# PCIE1_CORE_DBN_CFG_PCIE_CORE register map
Vendor: Texas Instruments
Registers are 32-bit, read-write, reset 0x0 unless marked. A register's access mark holds for its fields unless they carry their own. Offsets are as the file gives them; [hi:lo] are bit positions; {n}, {i} and the like mark numbered series; 'fields as' and 'values as' point back to an identical list.

## PCIE1_CORE_DBN_CFG_PCIE_CORE (part 5 of 7)
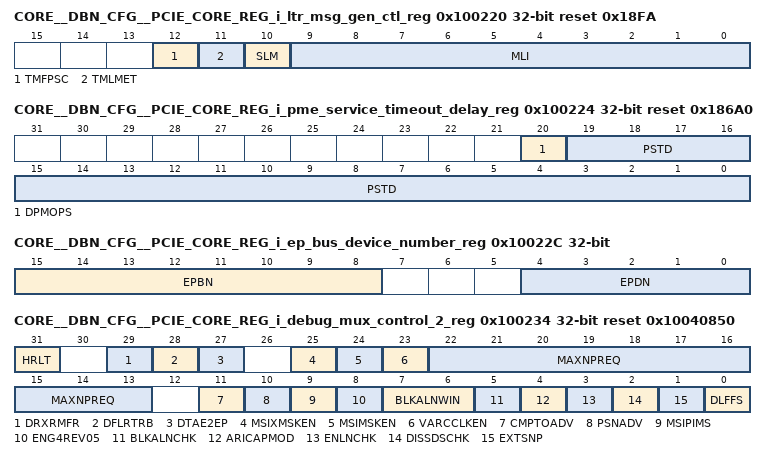
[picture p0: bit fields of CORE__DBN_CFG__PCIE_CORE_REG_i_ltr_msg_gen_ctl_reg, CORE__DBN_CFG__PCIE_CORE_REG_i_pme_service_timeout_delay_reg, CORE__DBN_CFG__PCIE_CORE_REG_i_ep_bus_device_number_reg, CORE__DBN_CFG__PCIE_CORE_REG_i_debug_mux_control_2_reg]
0x100220 CORE__DBN_CFG__PCIE_CORE_REG_i_ltr_msg_gen_ctl_reg access per field reset 0x18FA — This register contains fields for the generation of Latency Tolerance Reporting (LTR) Messages. This register is to be used only when the Controller is configured in the EndPoint mode.
  [12] TMFPSC rw — When this bit is set to 1, the Controller will automatically transmit an LTR message when all the Functions in the Controller have transitioned to a non-D0 power state, provided that the following conditions are both true: 1. The Controller sent at least one LTR message since the Data Link layer last transitioned from down to up state. 2. The most recent LTR message transmitted by the Controller had as least one of the Requirement bits set. The Controller will set the Requirement bits in this LTR message to 0. When this bit 12 is 0, the Controller will not, by itself, send any LTR messages in response to Function Power State changes. Client logic may monitor the FUNCTION_POWER_STATE outputs of the Controller and transmit LTR messages through the master interface, in response to changes in their states.
  [11] TMLMET rw — When this bit is set to 1, the Controller will automatically transmit an LTR message whenever the LTR Mechanism Enable bit in the Device Control 2 Register changes from 0 to 1, with the parameters specified in the LTR Snoop/No-Snoop Latency Register. When this bit is 1, the Controller will also transmit an LTR message whenever the LTR Mechanism Enable bit is cleared, if the following conditions are both true: 1. The Controller sent at least one LTR message since the LTR Mechanism Enable bit was last set. 2. The most recent LTR message transmitted by the Controller had as least one of the Requirement bits set. The Controller will set the Requirement bits in this LTR message to 0. When this bit 11 is 0, the Controller will not, by itself, send any LTR messages in response to state changes of the LTR Mechanism Enable bit. Client logic may monitor the state of the LTR_MECHANISM_ ENABLE output of the Controller and transmit LTR messages through the master interface, in response to its state changes.
  [10] SLM ro — Setting this bit causes the Controller to transmit an LTR message with the parameters specified in the LTR Snoop/No-Snoop Latency Register [Section 8.4.2.9]. This bit is cleared by the Controller on transmitting the LTR message, and stays set until then. Client software must read this register and verify that this bit is 0 before setting it again to send a new message. This field becomes writable when LTR mechanism is enabled in device control-2 register.
  [9:0] MLI rw — This field specifies the minimum spacing between LTR messages transmitted by the Controller in units of microseconds. The PCI Express Specifications recommend sending no more than two LTR messages within a 500 microsecond interval. The Controller will wait for the minimum delay specified by this field after sending an LTR message, before transmitting a new LTR message. NOTE: The LINK can be in low power states[L0s and L1] when send LTR Message is trigered. So, the user has to consider the exit latencies while programming this field. It is recommended to program this field with about 2 us higher than the required interval to account for the L0s/L1 exit latencies.
0x100224 CORE__DBN_CFG__PCIE_CORE_REG_i_pme_service_timeout_delay_reg reset 0x186A0 — This register stores the timeout delay parameter for the service timeout mechanism associated with the generation of PM_PME messages. In the EndPoint mode, the Controller will retransmit a PM_PME message after the expiration of this delay, if the Root Complex did not clear the PME Status bit in the Power Management Control and Status Register. This register is not used when the Controller is configured as Root Complex.
  [20] DPMOPS — When this bit is set, Controller will not automatically send a PME message, when PM Status bit in PMCSR register is set
  [19:0] PSTD — Specifies the timeout delay for retransmission of PM_PME messages. The value is in units of microseconds. The actual time elapsed has a +1 microseconds tolerance from the value programmed.
0x100228 CORE__DBN_CFG__PCIE_CORE_REG_i_root_port_requestor_id_reg — When the Controller is configured as Root Complex, this ID will be used for all internally generated messages.
  [15:0] RPRI — RID [bus, device and function numbers] for all TLPs internally generated by Root Port
0x10022C CORE__DBN_CFG__PCIE_CORE_REG_i_ep_bus_device_number_reg ro — When the Controller is configured as End Point, this register holds the Bus and Device number captured for Function 0
  [15:8] EPBN — Bus Number captured by Function 0 in End Point mode
  [4:0] EPDN — Device Number captured by Function 0 in End Point mode
0x100234 CORE__DBN_CFG__PCIE_CORE_REG_i_debug_mux_control_2_reg reset 0x10040850
  [31] HRLT — If set this bit makes the HOT_RESET_OUT signal behave as a level signal rather than a pulse. When set , the HOT_RESET_OUT will be asserted as long as the controller is in the HOT Reset state.
  [29] DRXRMFR — By default, when an Uncorrectable error is detected on a receive FIFO RAM, then no packets are read out of the RAM subsequent to the error and the RAMs are frozen. 0 : Receive FIFO RAMs are frozen after an uncorrectable error. 1 : Receive FIFO RAMs continue to read subsequent packets after an uncorrectable error.
  [28] DFLRTRB — 1 : NP Termination due to FLR/Completion Timeout is delayed till the RX Completion FIFO is Empty. 0 : NP Termination due to FLR is done immediately on receiving FLR/Completion Timeout.
  [27] DTAE2EP — By default, when End to End Parity error is detected on inbound/outbound data streams, then all the transmitted outbound packets will be Nullified by the Controller. This bit can be used to turn off nullifying Tx packets on End to End Parity Error.
  [25] MSIXMSKEN — By default, the Controller provides a single status bit when any function's MSIX Function Mask is programmed or configured by Local firmware or Host SW. Controller also implements an enhanced MSIX Function Mask Interrupt mechanism, which provides per-function set/clear status when a function's MSIX Function Mask is updated by SW. This Local Management programmable bit allows user to choose between the Default and Enhanced MSIX Function Mask Change Interrupt mechanisms.
  [24] MSIMSKEN — By default, the Controller provides a single status bit when any function's MSI Mask is programmed or configured by Local firmware or Host SW. Controller also implements an enhanced MSI Mask Interrupt mechanism, which provides per-function set/clear status when a function's MSI Mask is updated by SW. This Local Management programmable bit allows user to choose between the Default and Enhanced MSI Mask Change Interrupt mechanisms.
  [23] VARCCLKEN — If this bit is set the CORE_CLK input can be driven with Variable Clock depending on the Link Speed,similar to the PIPE_PCLK.
  [22:13] MAXNPREQ — The Controller supports 32 outstanding NP requests that can be initiated by the User. However, the number of split completion TLPs that can be stored in the Controller is limited to 128. The Completion FIFO will overflow if more than 128 split completion packets are pending. If the User interface can accept inbound Posted and Completion packets at the same rate as received from PCIe link, then the split completion FIFO will never reach the FULL condition. However, if the User cannot guarantee this, then this register needs to be programmed as described in the Programming Guide section of the Controller User guide. The Controller will limit the maximum number of outstanding NP requests to the value programmed in this register. Example: 8 : Controller will limit maximum number of outstanding NP requests to 8. 0-7 : Reserved Default Value is 32
  [11] CMPTOADV — As per PCIe specification on Error Signaling, the Requester detecting a Completion Timeout is allowed to handle this as an Advisory Non Fatal Error. 1: Completion Timeout is handled as Advisory Non-Fatal Error. 0: Completion Timeout is handled as normally as a Non-Fatal Error.
  [10] PSNADV — As per PCIe specification 2.7.2.2, the following Poisoned TLP requests must be handled as Uncorrectable and not as Advisory: I/O Write Request, Memory Write Request, or non-vendor-defined Message with data that target a Control structure. Since it is not possible for the Controller to determine if the target is a Control or a non-Control strusture, the Controller implements this bit for the user to determine the required handling. 1: Poisoned TLP of type IOWr, MemWr, MsgD will be handled as Advisory Non-Fatal Error. 0: Poisoned TLP of type IOWr, MemWr, MsgD will be handled as Uncorrectable Error. Note: Poisoned CplD will always be reported as Advisory Non-Fatal and is not controlled by this register setting.
  [9] MSIPIMS — If the Client wishes to use the MSI_PENDING_STATUS_IN Signal to Update the MSI pending Bits register, this bit needs to be set to 1. Otherwise the Pending Bits register is updated via the APB Interface
  [8] ENG4REV05 — When operating in Gen4 16GT/s , This Enables Gen4 Spec Revision 0.5 EIEOS and SKP features. When disabled, the Gen4 1.0 features are enabled, by default this bit is ZERO. 1: Enable Gen4 0.5 Features 0: Disable Gen4 0.5 Features [This enabled the Gen4 1.0 Features] .
  [7:6] BLKALNWIN — When in the data stream at Gen3 or higher speeds, the pipe_rx_valid is asserted by the PHY. If the block alignment is lost, then the PHY may deassert pipe_rx_valid. Controller reports loss of block alignment if pipe_rx_valid or pipe_rx_data_valid=0 for a period consecutive clock cycles as programmed in this field. 00: 8 CORE_CLK cycles 01: 16 CORE_CLK cycles 10: 64 CORE_CLK cycles 11: 256 CORE_CLK cycles
  [5] BLKALNCHK — When in the data stream at Gen3 or higher speeds, the pipe_rx_valid is asserted by the PHY. If the block alignment is lost, then the PHY may deassert pipe_rx_valid. Block Alignment may be lost if the received sync header is invalid. Controller supports detecting loss of block alignment while in a data stream in Gen3. 0: Enable check for loss of Gen3 Block Alignment during data stream. 1: Disable check for loss of Gen3 Block Alignment.
  [4] ARICAPMOD — As per SR IOC specification, ARI Capable Hierarchy bit is only present in the lowest numbered PF of a Device. The Controller has two modes to determine the lowest numbered PF. 0: the first PF which is enabled [PF0] is taken as the lowest numbered PF. 1: the first PF which has a non-zero TOTAL_VF_COUNT field is taken as the lowest numbered PF.[Default Mode]
  [3] ENLNCHK — As per PCIe specification, LTSSM should transition to Disabled after any Lanes that are transmitting TS1 Ordered Sets receive two consecutive TS1 Ordered Sets with the Disable Link bit asserted. Similarly, LTSSM should transition to Loopback after all Lanes that are transmitting TS1 Ordered Sets, that are also receiving TS1 Ordered Sets, receive the Loopback bit asserted in two consecutive TS1 Ordered Sets. Controller ignores the Link and Lane Number in the Received TS1s with Loopback/Disable bit set. Setting this bit to 1 turns on the check for link number [assigned by RC in Recovery.Idle] and lane number [PAD in Config.LW.Start or as assigned by RC in Recovery.Idle]. This bit is recommended to be kept at the default value of 0.
  [2] DISSDSCHK — As per PCIe specification, When using 128b/130b encoding, next state is L0 if eight consecutive Symbol Times of Idle data are received on all configured Lanes. The Controller checks to ensure that the Idle symbols of data are received in Data Blocks after SDS OS. This check is enabled by default. Setting this bit to 1 turns off this check. This bit is recommended to be kept at the default value of 0.
  [1] EXTSNP — This bit can be set if an extra clock cycle is required by the Client Application logic to respond with the Read Data on Configuration Snoop Interface. Please refer to the user guide section on Configuration Snoop Interface for timing diagrams.
  [0] DLFFS — As per PIPE 4.2 specification, the LOCALLF, LOCALFS outputs from PHY can be sampled uponf PHYSTATUS pulse after Reset# OR upon the first PHYSTATUS pulse after speed change to GEN3. This bit can be set to 1 to disable sampling after speed change to GEN3 or higher
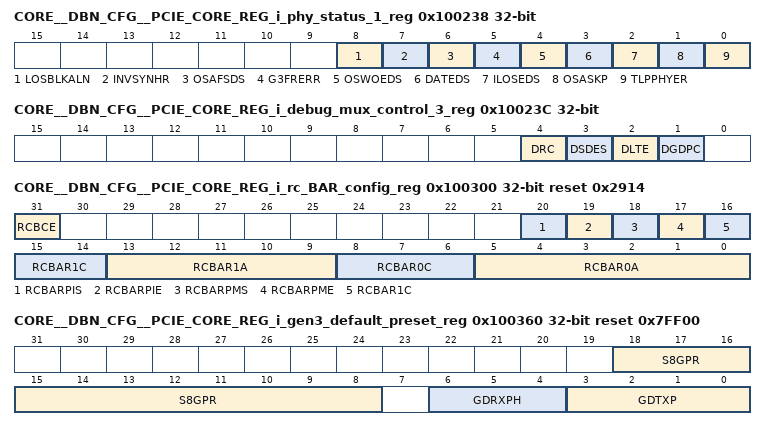
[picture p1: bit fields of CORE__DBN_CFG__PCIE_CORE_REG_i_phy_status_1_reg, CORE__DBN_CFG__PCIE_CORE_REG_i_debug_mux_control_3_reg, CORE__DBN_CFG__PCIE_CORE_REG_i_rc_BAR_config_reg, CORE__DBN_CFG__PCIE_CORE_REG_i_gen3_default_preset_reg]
0x100238 CORE__DBN_CFG__PCIE_CORE_REG_i_phy_status_1_reg access not given — This status register provides additional debug information about the PHY. Bits 8:0 provide information to debug Receiver Errors.
  [8] LOSBLKALN — This bit is set if the PHY Loses Block Alignment during data stream. This is detected based upon an unexpected PIPE_RX_VALID input deassertion during data stream. Write a 1 to clear this error. (access R/W1TC)
  [7] INVSYNHR — This bit is set if an invalid Sync Header is detected. 00 and 11 are Invalid Sync Headers. Write a 1 to clear this error. . (access R/W1TC)
  [6] OSAFSDS — This bit is set if an SDS is received after an SDS. This is a framing error. Write a 1 to clear this error. (access R/W1TC)
  [5] G3FRERR — This bit is set if a framing error is detected while receiving a TLP in Gen3. Example, if an invalid token is received in a data stream, this error is flagged. Write a 1 to clear this error. (access R/W1TC)
  [4] OSWOEDS — This bit is set if an Ordered Set Block is received without an EDS. This is a framing error. Write a 1 to clear this error. (access R/W1TC)
  [3] DATEDS — This bit is set if a Data Block is received after an EDS. Write a 1 to clear this error. (access R/W1TC)
  [2] ILOSEDS — The Valid OS blocks after an EDS are EIOS, EIEOS and SKP. If any other OS blocks are received after EDS, then it is a framing error and this bit is asserted. (access R/W1TC)
  [1] OSASKP — This bit indicates that an Ordered Set BLock was received immediately after a SKIP OS. This is a framing error. Write a 1 to clear this field. (access R/W1TC)
  [0] TLPPHYER — This bit indicates that a PHY Error was detected on the PIPE_RX_STATUS within a TLP. Write a 1 to clear this field. (access R/W1TC)
0x10023C CORE__DBN_CFG__PCIE_CORE_REG_i_debug_mux_control_3_reg
  [4] DRC — USed to disable and enable the RCB checker and by default it is enabled
  [3] DSDES — Used to disable and enable Surprise Down Error status logging and by default it is enabled
  [2] DLTE — Used to disable and enable link training error logging and by default it is enabled
  [1] DGDPC — To disable GEN4 data parity check from LM register
0x100300 CORE__DBN_CFG__PCIE_CORE_REG_i_rc_BAR_config_reg reset 0x2914 — The root complex side of the Controller contains two memory BARs that can be used for address-range checking of incoming requests from devices connected to it. The fields in this register determine the configuration of these BARs.
  [31] RCBCE — This bit must be set to 1 to enable BAR checking in the RC mode. When this bit is set to 0, the Controller will forward all incoming memory requests to the client logic without checking their address ranges.
  [20] RCBARPIS — Width of IO Base and Limit registers in type1 config space. 0=32 bits, 1=64bits
  [19] RCBARPIE — Enable for IO Base and Limit registers in type1 config space
  [18] RCBARPMS — Width of Prefetchable Memory Base and Limit registers in type1 config space. 0=32 bits, 1=64bits
  [17] RCBARPME — Enable for Prefetchable memory base and limit registers in type1 config space
  [16:14] RCBAR1C — Specifies the configuration of RC BAR1. The various encodings are: 000: Disabled 001: 32bit IO BAR 010-011: Reserved 100: 32bit memory BAR, non prefetchable 101: 32bit memory BAR, prefetchable 110-111: Reserved
  [13:9] RCBAR1A — This field specifies the aperture of the RC BAR 1. The encodings are: 0000 = 4, 00001 =8B,..... 1_1101 = 2G
  [8:6] RCBAR0C — Specifies the configuration of RC BAR0. The various encodings are: 000: Disabled 001: 32bit IO BAR 010-011: Reserved 100: 32bit memory BAR, non prefetchable 101: 32bit memory BAR, prefetchable 110: 64bit memory BAR, non prefetchable 111: 64bit memory BAR, prefetchable
  [5:0] RCBAR0A — This field specifies the aperture of the RC BAR 0. The encodings are: 0000 = 4, 00001 =8B,..... 01_1111 = 8G, ....10_0100 = 256G.
0x100360 CORE__DBN_CFG__PCIE_CORE_REG_i_gen3_default_preset_reg reset 0x7FF00 — This is register specifies the default transmitter preset and default receiver preset hint used by Controller for lanes that have not received EQ TS2s during Recovery.RcvrConfig LTSSM state
  [18:8] S8GPR — This register can be used to program the Presets that are supported by local Transmitter at 8Gbps. Default value of this register is determined by the SUPPORTED_PRESET strap input. Note: At 8.0 GT/s and 16.0 GT/s all preset values must be supported for Full swing signaling. Reduced swing signaling must implement presets #4, #1, #9, #5, #6, and #3.
  [6:4] GDRXPH — Default receiver preset hint value used for a lane that did not receive EQ TS2 in Recovery.RcvrCfg LTSSM state
  [3:0] GDTXP — Default transmitter preset value used for a lane that did not receive EQ TS2 in Recovery.RcvrCfg LTSSM state
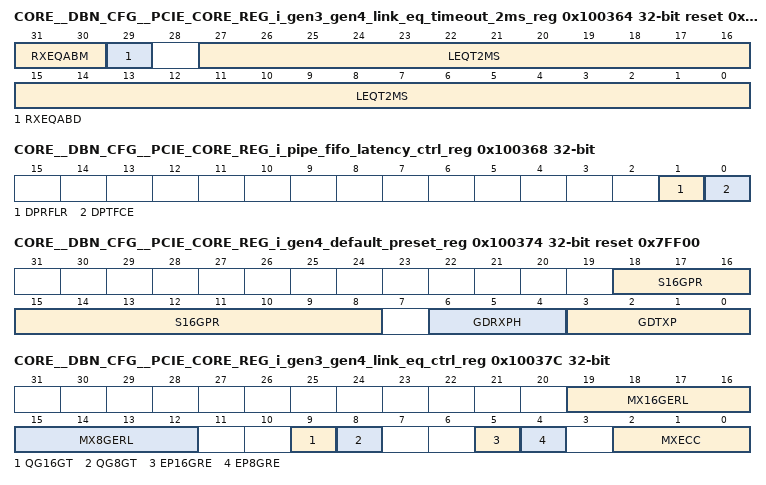
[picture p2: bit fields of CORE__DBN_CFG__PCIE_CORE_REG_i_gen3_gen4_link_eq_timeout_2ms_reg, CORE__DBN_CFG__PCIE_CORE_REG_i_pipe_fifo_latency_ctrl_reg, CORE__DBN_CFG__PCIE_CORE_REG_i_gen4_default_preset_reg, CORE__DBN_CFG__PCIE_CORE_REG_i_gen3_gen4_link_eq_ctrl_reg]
0x100364 CORE__DBN_CFG__PCIE_CORE_REG_i_gen3_gen4_link_eq_timeout_2ms_reg reset 0xC001E848 — This register is used to tune the time spent for evaluation per TX Setting in Endpoint Phase 2 (RC Mode Phase 3) of GEN3, GEN4 Link Equalization. The PCIe Spec defines a timeout of 2ms per TX setting and hence the default value for this register is set to 2ms. This can be tweaked based on the total number of iterations done and the time required for the PHY to respond with feedback for RXEQEVAL request. The total time taken in Endpoint Phase 2 (RC Mode Phase 3) must be less than 24 ms as defined by spec. Guideline: (Total Number of iterations)*(link_eq_timeout_2ms_reg + max time required for PHY to respond to RXEQEVAL) less than 24ms
  [31:30] RXEQABM — When a 24ms timeout occurs in the LTSSM Equalization Phase 2, the Controller aborts Equalization Phase 2 and transitions to Recovery.Rcvr.Lock. In this case, the RxEqEval output on the PIPE Interface will be de-asserted immediately [if it was asserted]. The RxEqInProgress output will stay high and waits for PhyStatus pulse. Controller implements a timer to select an upper limit to wait for this PhyStatus pulse during an abort to de-assert RxEqInProgress. 00: Wait for a maximum of 4 PIPE_PCLK period. 01: Wait for a maximum of 8 PIPE_PCLK period. 10: Wait for a maximum of 16 PIPE_PCLK period. 11: Disabled. Wait till PhyStatus Pulse is received. Note: This register is used only if RxEqEval was asserted when LTSSM 24ms timeout occured in Equalization.
  [29] RXEQABD — In an unexpected case where the PIPE_PCLK stops due to error in equalization, this bit can be set to de-couple RxEqInProgress from the rest of the equalization state machine. This bit should not be set for normal usage.
  [27:0] LEQT2MS — Time spent for evaluation per TX Setting in Endpoint Phase 2 [RC Mode Phase 3] of Link Equalization specified in multiples of 16ns. eg. the value 125000 will result in 125000*16ns = 2ms. Simulation with reduced time mode[PCIE_SIM define] will give a samller value of 300 as power on reset value.
0x100368 CORE__DBN_CFG__PCIE_CORE_REG_i_pipe_fifo_latency_ctrl_reg — This is register includes bits to control pipe fifo latency
  [1] DPRFLR — 0: If FIFO empty is reached, the PIPE RX FIFO accumulates 2 entries before reading the FIFO again. 1: If FIFO empty is reached, the PIPE RX FIFO accumulates 6 entries before reading the FIFO again. This is to prevent FIFO from reaching empty again. Default value of this bit is 0, in order to reduce the latency through the PIPE RX FIFO.
  [0] DPTFCE — By default, if FIFO empty is reached, the PIPE TX FIFO accumulates 2 entries before reading the FIFO again. This is to prevent FIFO from reaching empty again. This bit must remain at 0 to allow the PIPE TX FIFO to recover effectively from a Empty condition.
0x100374 CORE__DBN_CFG__PCIE_CORE_REG_i_gen4_default_preset_reg reset 0x7FF00 — This is register specifies the default transmitter preset and default receiver preset hint used by Controller for lanes that have not received 16G EQ TS2s during Recovery.RcvrConfig LTSSM state
  [18:8] S16GPR — This register can be used to program the Presets that are supported by local Transmitter at 16Gbps. Default value of this register is determined by the SUPPORTED_PRESET strap input. Note: At 8.0 GT/s and 16.0 GT/s all preset values must be supported for Full swing signaling. Reduced swing signaling must implement presets #4, #1, #9, #5, #6, and #3.
  [6:4] GDRXPH — Default Gen4 receiver preset hint value used for a lane that did not receive 16G EQ TS2 in Recovery.RcvrCfg LTSSM state
  [3:0] GDTXP — Default Gen4 transmitter preset value used for a lane that did not receive 16G EQ TS2 in Recovery.RcvrCfg LTSSM state
0x100378 CORE__DBN_CFG__PCIE_CORE_REG_i_phy_config_reg3 reset 0x80 — This is register specifies the PHY Specific registers for used in Gen4
  [7:0] TFC4 — FTS count transmitted by the Controller in TS1/TS2 sequences during link training. This value must be set based on the time needed by the receiver to acquire sync while exiting from L0S state at 16 GT/s speed.
0x10037C CORE__DBN_CFG__PCIE_CORE_REG_i_gen3_gen4_link_eq_ctrl_reg — This register is used to Control GEN3, GEN4 Link Equalization Procedure.
  [19:16] MX16GERL — The number of 16GT/s Equalization Requests must be finite as per PCIe specification. This register can be used to program the maximum number of 16GT/s equalization requests automatically initiated by the Endpoint. 0000: Automatic 16GT/s Equalization Request Disabled. 0001: Automatic 16GT/s Equalization request limit is 1. 0010: Automatic 16GT/s Equalization request limit is 2. .... 1111: Automatic 16GT/s Equalization request limit is 15,
  [15:12] MX8GERL — The number of 8GT/s Equalization Requests must be finite as per PCIe specification. This register can be used to program the maximum number of 8GT/s equalization requests automatically initiated by the Endpoint. 0000: Automatic 8GT/s Equalization Request Disabled. 0001: Automatic 8GT/s Equalization request limit is 1. 0010: Automatic 8GT/s Equalization request limit is 2. .... 1111: Automatic 8GT/s Equalization request limit is 15,
  [9] QG16GT — This bit can be used to program the Quiesce Guarantee bit of the TS2 in Recovery.Rcvr.Cfg state during 16GT/s Request Equalization.
  [8] QG8GT — This bit can be used to program the Quiesce Guarantee bit of the TS2 in Recovery.Rcvr.Cfg state during 8GT/s Request Equalization.
  [5] EP16GRE — Writing a 1 into this field results in the Controller to transition to Recovery. The Request Equalization bit and Equalization Request Data Rate bit in TS2 Ordered Sets will be set to 1 in Recovery.Rcvr.Cfg to request equalization at 16GTs. This bit is auto-cleared by the internal logic of the Controller after the re-training has been completed and link has reached the L0 state. This bit is also auto-cleared when not in Gen3 or Gen4. Device Firmware must wait for the bit to be clear before any subsequent requests.
  [4] EP8GRE — This bit can be used by Endpoint Device FW to request for 8GT/s Equalization redo. This bit can be set at any time after the Link is Up. Writing a 1 into this field results in the Controller to transition to Recovery. The Request Equalization bit in TS2 Ordered Sets will be set to 1 in Recovery.Rcvr.Cfg to request equalization at 8GTs. This bit is auto-cleared by the internal logic of the Controller after the re-training has been completed and link has reached the L0 state. This bit is also auto-cleared when not in Gen3 or Gen4. Device Firmware must wait for the bit to be clear before any subsequent retrain requests.
  [2:0] MXECC — Controls the number of consecutive RxEqEval iterations with direction change feedback of 00s before Equalization Convergence is inferred. 0 : Infer Convergence after 1 feedback of 000000 1 : Infer Convergence after 2 feedback of 000000 2 : Infer Convergence after 3 consecutive feedback of 000000 .. 7 : Infer Convergence after 8 consecutive feedback of 000000. Note: Each lane independently counts consecutive feedback of 000000. Note: Count is reset after a non-000000 feedback on each lane.
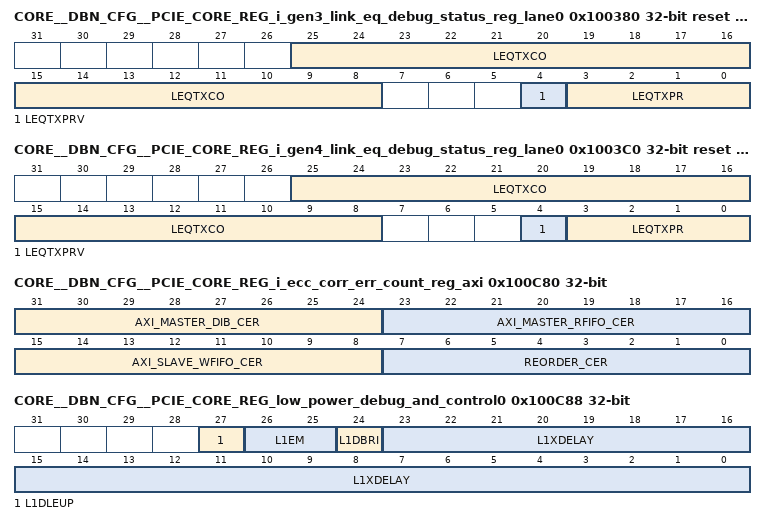
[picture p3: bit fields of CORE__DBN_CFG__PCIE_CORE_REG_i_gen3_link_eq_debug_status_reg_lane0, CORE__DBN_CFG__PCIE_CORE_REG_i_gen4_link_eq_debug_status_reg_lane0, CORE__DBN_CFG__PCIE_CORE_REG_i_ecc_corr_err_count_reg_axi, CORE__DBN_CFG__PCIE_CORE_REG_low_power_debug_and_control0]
{0x100380+4i} CORE__DBN_CFG__PCIE_CORE_REG_i_gen3_link_eq_debug_status_reg_lane{i} ro reset 0xB4004 (i=0..3) — This register is used to reflect the negotiated TX Preset, Coefficients at the end of GEN3 Link Equalization. When the Controller is an Endpoint, this register reflects the Preset/Coefficients applied to the Endpoint Transmitter at the end of Gen3 Equalization Phase 3. When the Controller is an RC, this register reflects the Preset/Coefficients applied to the RC Transmitter at the end of Gen3 Equalization Phase 2.
  [25:8] LEQTXCO — TX Coefficients agreed upon for this lane. [25:20] : Post Cursor Coefficient [19:14] : Cursor Coefficient [13:8] : Pre-Cusror Coefficient
  [4] LEQTXPRV — TX Preset Valid Indicator. This bit is set when a TX Preset is received in TS1s with the use_preset bit set in Endpoint Mode Phase 3 or RC Mode Phase 2.
  [3:0] LEQTXPR — TX Preset agreed upon for this lane
{0x1003C0+4i} CORE__DBN_CFG__PCIE_CORE_REG_i_gen4_link_eq_debug_status_reg_lane{i} ro reset 0x684608 (i=0..3) — This register is used to reflect the negotiated TX Preset, Coefficients at the end of GEN4 Link Equalization. When the Controller is an Endpoint, this register reflects the Preset/Coefficients applied to the Endpoint Transmitter at the end of Gen4 Equalization Phase 3. When the Controller is an RC, this register reflects the Preset/Coefficients applied to the RC Transmitter at the end of Gen4 Equalization Phase 2.
  fields as CORE__DBN_CFG__PCIE_CORE_REG_i_gen3_link_eq_debug_status_reg_lane0
0x100C80 CORE__DBN_CFG__PCIE_CORE_REG_i_ecc_corr_err_count_reg_axi access not given — This register contains the count of the number of ECC errors detected and corrected during reads from PCIe core AXI external RAMs.
  [31:24] AXI_MASTER_DIB_CER — Number of correctable errors detected while reading from the AXI Master Read Data interleave RAM. This is an 8-bit saturating counter that can be cleared by writing all 1s into it. (access R/W1TC)
  [23:16] AXI_MASTER_RFIFO_CER — Number of correctable errors detected while reading from the AXI master read fifo RAM. This is an 8-bit saturating counter that can be cleared by writing all 1's into it. (access R/W1TC)
  [15:8] AXI_SLAVE_WFIFO_CER — Number of correctable errors detected while reading from the AXI slave write fifo RAM. This is an 8-bit saturating counter that can be cleared by writing all 1's into it. (access R/W1TC)
  [7:0] REORDER_CER — Number of correctable errors detected while reading from the AXI slave reorder RAM. This is an 8-bit saturating counter that can be cleared by writing all 1's into it. (access R/W1TC)
0x100C88 CORE__DBN_CFG__PCIE_CORE_REG_low_power_debug_and_control0 access per field — This register controls internal behavior of controller for low power operations. Adjustment of this register is not required for normal operations.
  [27] L1DLEUP rw — Pending Tlps trigger a L1 exit by default. This includes internaly generated messages and internaly blocked TLPs. Setting this bit changes the default behavior. This is required only for debug purpose.
  [26:25] L1EM ro — This field shows the last entered L1 mode. This is useful for debug. bit 0 - Entry mode was ASPM. Bit 1 - Entry mode was PM. This is reset before any new L1 entry.
  [24] L1DBRI rw — Before entering L1, controller internally blocks all TLP and Register Request interface entering controller. interfaces are internally unblocked while exiting L1. This field control this behavior. '1' in this field makes the controler to do not perform any blocking to interfaces. '0' makes the controller behaves normaly. This is required only for debug purpose. Power shutoff feature has to be disabled while using this field.
  [23:0] L1XDELAY rw — Normaly L1 substate entry process is initiated immedaitely after LTSSM enters L1. A delay in micro-seconds can be given in this field to delay L1 substate entry process. This timeout has 0-1us margin of error. Power on reset value of this register can be adjusted by modifying the define den_db_LP_DBG_CTRL_L1_SUBSTATE_ENTRY_DELAY
0x100C8C CORE__DBN_CFG__PCIE_CORE_REG_low_power_debug_and_control1 ro — This register controls internal behavior of controller for low power operations. Adjustment of this register is not required for normal operations.
  [7:0] L1ER — This field shows the values of possible L1 or L1-substate exit triggers. This is useful for debug. this is captured during L1 or L1-substate exit process. this field is reset during L1 entry. 0 : CLIENT_REQ_EXIT_L1 asserted; 1 : Electrical Idle exit detected at link; 2 : New TLP request detected; 3 : Internal request to send TLP. This includes CFG completions. internal messages. INTx messages; 4 : Pending TX traffic available. This could be traffic from DMA and blocked traffic due to credits at AXI.; 5 : #CLKREQ assert detected; 6 : CLIENT_REQ_EXIT_L1_SUBSTATE asserted 7 : Reg Access request detected; Triggers #5,6,7 are valid only with L1-substate supported configs.
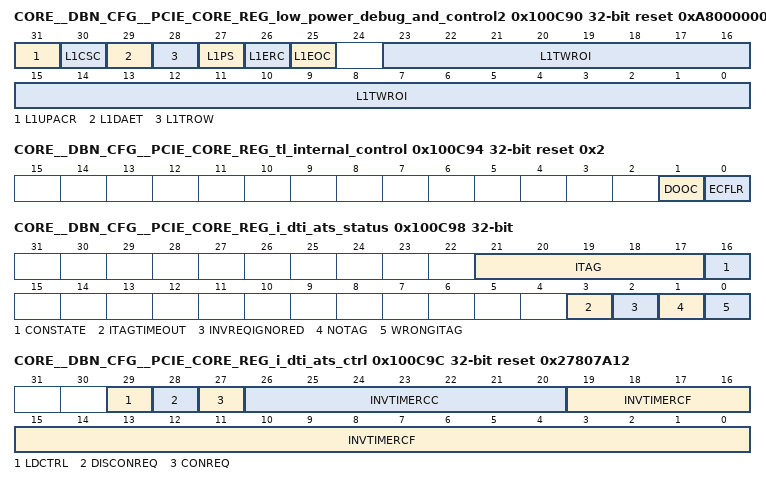
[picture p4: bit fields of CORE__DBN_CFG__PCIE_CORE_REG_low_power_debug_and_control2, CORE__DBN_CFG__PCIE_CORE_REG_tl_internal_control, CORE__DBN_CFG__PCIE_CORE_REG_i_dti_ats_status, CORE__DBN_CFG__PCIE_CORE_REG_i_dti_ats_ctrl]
0x100C90 CORE__DBN_CFG__PCIE_CORE_REG_low_power_debug_and_control2 access per field reset 0xA8000000 — This register controls internal behavior of controller for low power operations. Adjustment of this register is not required for normal operations.
  [31] L1UPACR rw — Setting this field make the state machine to consider LP_CTRL_POWER_RECOVER_ACK as Client system recovery Complete ACK instead of the Controller power stable ACK. This field is ignored if LP_CTRL_BYPASS_ENABLE unset. If this field is set, L1-substate machines expect that the client system finishes power up of the controller within power_on time in the L1-substate capability register and Controller will be waiting in recovery state for ACK. This ensure that the PHY PLL lock and client system initialization goes on in parallel. Default value of this register can be set with the define:den_db_LP_DBG_CTRL_RECOVER_ACK_AS_CLIENT_RECOVER_ACK. Setting this field gives the best system performance.
  [30] L1CSC rw — L1-substate removes CORE_CLK. since the registers are implemented in core-clk, register access is not possible during L1-substate. If client can supply a slow clock to core[CORE_CLK] during L1-substates, APB/mgmt access is possible in L1.x. set this bit if client can supply slow clock to CORE_CLK when CLKREQ_IN_N is 1[de-asserted]. If this bit is set, Controller neither wake-up from L1 or generate error response for APB access during L1.x. Controller behavior is undefined if register write is performed while slow clock is supplied to core_clk. Recommended flow is to first exit from L1-substate and perform register writes. Power on reset value of this register can be adjusted by modifying the define den_db_LP_DBG_CTRL_CLIENT_SUPPLIES_SLOW_CLK_TO_CORE_DURING_L1
  [29] L1DAET rw — L1.x turns off clocks to the controller. Default behavior is made to exit L1.x if Register access request is present at register interface. Setting this bit disables this feature. If this bit is set and CLKREQ_IN_N is 1[de-asserted], Controller responds with ERROR response to APB requests. Client can use CLIENT_EXIT_L1_SUBSTATE pin to trigger L1.x exit if autonomous exit is disabled for register access. This bit is ignored if L1 substate is disabled. Power on reset value of this register can be adjusted by modifying the define den_db_LP_DBG_CTRL_DISABLE_AUTONOMOUS_L1_EXIT_ON_NEW_REG_REQ
  [28] L1TROW ro — This is a debug status field. '1' in this field indicates that a timeout has occured while waiting for RX path or OUTstanding packet IDLE conditions. This is cleared on new entry to L1.
  [27] L1PS rw — This field enabled power shutoff mechanism in L1.2 state. This field is ignored if L1.x is not enabled. Power on reset value of this register can be adjusted by modifying the define den_db_LP_DBG_CTRL_POWER_SHUTOFF_ENABLE
  [26] L1ERC rw — Enables waiting for RX path IDLE condition before entering L1.x. This checks that all packets from PCIE link has reached client side before entering L1.x. This only a tuning register. Not setting this regsiter will cause controller to enter L1.x to save power without checking this. controller will resume transferring RX data once it exit from L1.x state if RX buffers were not empty. This field is ignored if Power shutoff mechanism is enabled for L1.x and Controller will always check RX path idle condition before turning off internal power[with cpf flow]. If timeout is enabled, controller enters L1.x without internal power shutoff after timeout. This bit is ignored if L1 substate is disabled. Power on reset value of this register can be adjusted by modifying the define den_db_LP_DBG_CTRL_WAIT_FOR_RX_BUFFER_IDLE
  [25] L1EOC rw — Enable waiting for outstanding completions before entering L1.x. Outstanding packets expected from pcie link as well as from AXI side is checked. FOR HAL configurations client has to assert PREVENT_L1x_ENTRY signal to prevent L1x entry. This only a tuning register. Not setting this regsiter will cause controller to enter L1.x to save power without checking this. controller exit from L1.x as soon as it receives expected TLps. This field is ignored if Power shutoff mechanism is selected for L1.x and Controller will always wait for outstanding packets before turning off internal power[with cpf flow]. If timeout is enabled, controller enters L1.x without internal power shutoff after timeout. This bit is ignored if L1 substate is disabled. Power on reset value of this register can be adjusted by modifying the define den_db_LP_DBG_CTRL_WAIT_FOR_OUTSTANDING_CPLS
  [23:0] L1TWROI rw — This field enables a timeout mechanism while waiting for RX buffers and Outstanding Pkts before turning off power. Controller enters L1 substate after timeout. A value of 0x0 disables this timeout mechanism. Controller do not select internal power shutoff if it enters L1.x with this timeout. User can give timeout in micro-seconds using this register. This field is ignored if L1 substate is disabled. Power on reset value of this register can be adjusted by modifying the define den_db_LP_DBG_CTRL_RX_CPL_IDLE_CHECK_TIMEOUT
0x100C94 CORE__DBN_CFG__PCIE_CORE_REG_tl_internal_control reset 0x2 — This register controls internal behavior of Transaction layer of controller. Adjustment of this register is not required for normal operations.
  [1] DOOC — Ordering between outbound Completions and posted packets are maintainted in transaction layer. This is achieved by blocking Completions if required. Completions arrived after EOP of a posted packet are blocked till that posted packet is transmitted. This Ordering check is required to conform to the PCIe ordering rules. This ordering check can be disabled by setting this field. Power on reset value of this register can be adjusted by modifying the define den_db_TL_CTRL_DISABLE_OB_ORDERING_CHECK
  [0] ECFLR — By default controller ignores config request if a function is under going FLR. Setting this bit Makes the controller to respond with CRS response. Power on reset value of this register can be adjusted by modifying the define den_db_TL_CTRL_ENABLE_CRS_UNDER_FLR
0x100C98 CORE__DBN_CFG__PCIE_CORE_REG_i_dti_ats_status access not given — This register is for reporting different error conditions/ State in DTI ATS Master
  [21:17] ITAG ro — Itag value which timed out
  [16] CONSTATE ro — When set indicates the DTI Master in connected state
  [3] ITAGTIMEOUT — When set indicates a timeout in one of the invalidation tags. Invalidation Tag timeout duration = INVTIMERCF * 16ns * INVTIMERCC (access R/W1TC)
  [2] INVREQIGNORED — When set indicates that the invalidation request is ignored internally by the DTI Master block (access R/W1TC)
  [1] NOTAG — When set indicates the DTI Slave returned an error for the connection request due to non availability of tags. (access R/W1TC)
  [0] WRONGITAG — When set indicates that the itag field is wrong in the invalidation completion message. (access R/W1TC)
0x100C9C CORE__DBN_CFG__PCIE_CORE_REG_i_dti_ats_ctrl reset 0x27807A12 — This register is for the control of DTI ATS Master
  [29] LDCTRL — This bit when programmed to 1 sends a disconnect request when link down reset happens and sends a connect request when link down indication bit is cleared.
  [28] DISCONREQ — When set DTI Master triggers a disconnect sequence to the DTI Slave. This bit gets reset to 0 when the DTI master establishes a disconnection.
  [27] CONREQ — When set DTI Master triggers a connect sequence to the DTI Slave. This bit gets reset to 0 when the DTI master establishes a connection.
  [26:20] INVTIMERCC — This is a coarse value which the individual invalidation timers check for reporting a timeout
  [19:0] INVTIMERCF — This is a master counter timeout value which triggers the invalidation tag timers to increment if an active invalidation request is present
0x100CC0 CORE__DBN_CFG__PCIE_CORE_REG_i_scaled_flow_control_mgmt_vc_select_reg — Scaled Flow Control registers are implemented per VC. The VC is selected using this register.
  [3:0] SFCVCS — The scaled flow management rgeister is implemented per VC. However, to limit the number of registers, only one VC can be accessed at a time. This register is used to select the VC for which Scaled Flow Control Management Register is to be accessed.
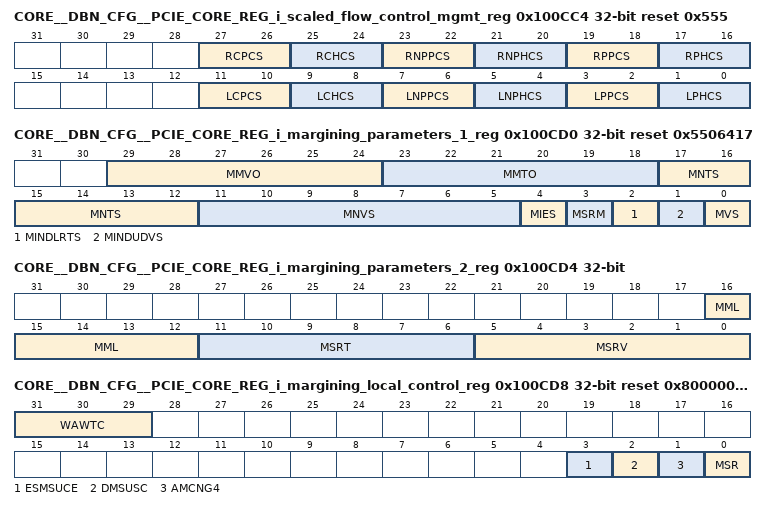
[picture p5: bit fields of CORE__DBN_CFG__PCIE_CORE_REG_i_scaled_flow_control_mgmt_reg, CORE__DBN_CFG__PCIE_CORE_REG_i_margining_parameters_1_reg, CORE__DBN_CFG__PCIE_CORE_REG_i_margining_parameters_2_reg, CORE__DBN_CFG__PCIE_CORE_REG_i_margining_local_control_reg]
0x100CC4 CORE__DBN_CFG__PCIE_CORE_REG_i_scaled_flow_control_mgmt_reg access per field reset 0x555 — Scaled Flow Control management register. For multi-VC configurations, this register accesses the VC selected in Scaled Flow Control VC Select register.
  [27:26] RCPCS ro — This register reflects the Completion Payload Credit Scale that is advertised by the remote end device during DL Feature Exchange.
  [25:24] RCHCS ro — This register reflects the Completion Header Credit Scale that is advertised by the remote end device during DL Feature Exchange.
  [23:22] RNPPCS ro — This register reflects the Non Posted Payload Credit Scale that is advertised by the remote end device during DL Feature Exchange.
  [21:20] RNPHCS ro — This register reflects the Non Posted Header Credit Scale that is advertised by the remote end device during DL Feature Exchange.
  [19:18] RPPCS ro — This register reflects the Posted Payload Credit Scale that is advertised by the remote end device during DL Feature Exchange.
  [17:16] RPHCS ro — This register reflects the Posted Header Credit Scale that is advertised by the remote end device during DL Feature Exchange.
  [11:10] LCPCS rw — This register can be used to program the Completion Payload Credit Scale that will be advertised by the Controller.
  [9:8] LCHCS rw — This register can be used to program the Completion Header Credit Scale that will be advertised by the Controller.
  [7:6] LNPPCS rw — This register can be used to program the Non Posted Payload Credit Scale that will be advertised by the Controller.
  [5:4] LNPHCS rw — This register can be used to program the Non Posted Header Credit Scale that will be advertised by the Controller.
  [3:2] LPPCS rw — This register can be used to program the Posted Payload Credit Scale that will be advertised by the Controller.
  [1:0] LPHCS rw — This register can be used to program the Posted Header Credit Scale that will be advertised by the Controller.
0x100CD0 CORE__DBN_CFG__PCIE_CORE_REG_i_margining_parameters_1_reg reset 0x5506417 — The Lane Margining at Receiver Parameters of the PHY are advertised in this Register.
  [29:24] MMVO — Offset from default at maximum step value as percentage of one volt. A 0 value may be reported if the vendor chooses not to report the offset.
  [23:18] MMTO — Offset from default at maximum step value as percentage of a nominal UI at 16.0 GT/s A 0 value may be reported if the vendor chooses not to report the offset.
  [17:12] MNTS — Number of time steps from default [to either left or right], range must be at least +/-0.2 UI. Timing offset must increase monotonically. The number of steps in both positive [toward the end of the unit interval] and negative [toward the beginning of the unit interval] must be identical.
  [11:5] MNVS — Number of voltage steps from default [either up or down], minimum range +/-50 mV as measured by 16.0 GT/s reference equalizer Voltage offset must increase monotonically. The number of steps in both positive and negative direction from the default sample location must be identical This value is undefined if M VoltageSupported is 0b.
  [4] MIES — 1b Margining will not produce errors [change in the error rate] in data stream [error sampler is independent] 0b Margining may produce errors in the data stream
  [3] MSRM — 1b - Sampling Rates M SamplingRateVoltage, M SamplingRateTiming are supported 0b - Sample Count is supported
  [2] MINDLRTS — 1b - Independent Left/Right Timing Margining is supported 0b - Independent Left/Right Timing Margining is not supported
  [1] MINDUDVS — 1b - Independent Up Down Voltage Margining is supported 0b - Independent Up Down Voltage Margining is not supported
  [0] MVS — 1b - Voltage Margining is supported 0b - Voltage Margining is not supported
0x100CD4 CORE__DBN_CFG__PCIE_CORE_REG_i_margining_parameters_2_reg — The Lane Margining at Receiver Parameters of the PHY are advertised in this Register.
  [16:12] MML — Maximum number of Lanes minus 1 that can be margined at the same time. It is recommended that this value be greater than or equal to the number of Lanes in the Link minus 1. Encoding Behavior is undefined if software attempts to margin more than MMaxLanes+1 at the same time. Note: This value is permitted to exceed the number of Lanes in the Link minus 1.
  [11:6] MSRT — The ratio of bits tested to bits received during timing margining. A value of 0 is a ratio of 1:64 [1 bit of every 64 bits received], and a value of 63 is a ratio of 64:64 [all bits received].
  [5:0] MSRV — The ratio of bits tested to bits received during voltage margining. A value of 0 is a ratio of 1:64 [1 bit of every 64 bits received], and a value of 63 is a ratio of 64:64 [all bits received].
0x100CD8 CORE__DBN_CFG__PCIE_CORE_REG_i_margining_local_control_reg reset 0x80000000 — The Lane Margining at Receiver local control fields are implemented in this Register.
  [31:29] WAWTC — When a WriteCommitted command is issued by the Controller, the PHY must respond with a Write_Ack response. The time for which the Controller waits before timing out is controlled by this register. 000: 10us 001: 100us 010: 1ms 011: 2ms 100: 10ms [default] 101: 20ms 110: 100ms 111: No Timeout
  [3] ESMSUCE — 0: [Default Value] When a Clear Error Log Command is received after a Step Margin Command, the Controller will process the Clear Error Log and respond with Clear Error Log Status. The Step Margin command is still active in the PHY. However, the Step Margin status will not be reflected in the Margin Status Register since the Margin Control Register holds Clear Error Log Command. Host Margining SW needs to configure the Step Margin Command again in order to get the Step Margin Status. 1: When this bit is set to 1, the Controller waits for Host SW to read the Clear Error Log Status through a CfgRd. After the Host read the Clear Error Log status, the Controller updates the latest Step Margin Status on to the Margin Status Register while the Margin Control Register holds Clear Error Log Command.
  [2] DMSUSC — By default, when a Step Margin command is received, the Controller will update Lane Margin status to Margining in Progress when an Error Count update Or a Sample Count update is received from PHY. Set this bit to 1 to not update Lane Margin Status on a Sample Count update from PHY.
  [1] AMCNG4 — By default, the Controller will process a Margin Command only if it is received while in 16GT/s L0 State. If a Margin Command is received when the link is not in Gen4-L0 state, then the command will be ignored. If this bit is set, then the Controller accepts and stores a margin command that is received when not in Gen4 L0 state. This command will be processed when the link reaches Gen4 L0 state.
  [0] MSR — This bit can be used to reset the Margining internal registers and Margining state machines in the Controller. When asserted: [i] The State machines will be reset to their default values. [ii] All internal FIFOs will be cleared. [iii] All the P2M and M2P registers will be reset. [iv] This does not reset the Margining Configuration and Management Registers. Margining Status register will show the last recorded status. This bit will automatically self-clear after 32-CORE_CLK cycles.
